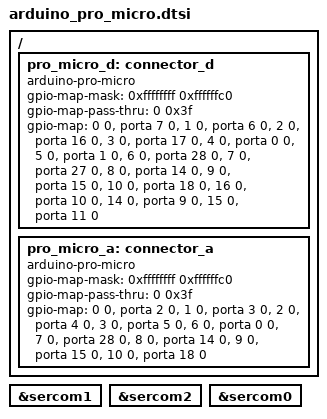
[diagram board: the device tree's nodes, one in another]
/*
 * Copyright (c) 2020 Pete Johanson
 *
 * SPDX-License-Identifier: MIT
 */

/ {
	pro_micro_d: connector_d {
		compatible = "arduino-pro-micro";
		#gpio-cells = <2>;
		gpio-map-mask = <0xffffffff 0xffffffc0>;
		gpio-map-pass-thru = <0 0x3f>;
		gpio-map
			= <0 0 &porta 7 0>		/* D0 */
			, <1 0 &porta 6 0>		/* D1 */
			, <2 0 &porta 16 0>		/* D2 */
			, <3 0 &porta 17 0>		/* D3 */
			, <4 0 &porta 0 0>		/* D4/A6 */
			, <5 0 &porta 1 0>		/* D5 */
			, <6 0 &porta 28 0>		/* D6/A7 */
			, <7 0 &porta 27 0>		/* D7 */
			, <8 0 &porta 14 0>		/* D8/A8 */
			, <9 0 &porta 15 0>		/* D9/A9 */
			, <10 0 &porta 18 0>		/* D10/A10 */
			, <16 0 &porta 10 0>	/* D16 */
			, <14 0 &porta 9 0>	/* D14 */
			, <15 0 &porta 11 0>	/* D15 */
			;
	};

	pro_micro_a: connector_a {
		compatible = "arduino-pro-micro";
		#gpio-cells = <2>;
		gpio-map-mask = <0xffffffff 0xffffffc0>;
		gpio-map-pass-thru = <0 0x3f>;
		gpio-map
			= <0 0 &porta 2 0>	/* A0 */
			, <1 0 &porta 3 0>	/* A1 */
			, <2 0 &porta 4 0>	/* A2 */
			, <3 0 &porta 5 0>	/* A3 */
			, <6 0 &porta 0 0>	/* D4/A6 */
			, <7 0 &porta 28 0>	/* D6/A7 */
			, <8 0 &porta 14 0>	/* D8/A8 */
			, <9 0 &porta 15 0>	/* D9/A9 */
			, <10 0 &porta 18 0>	/* D10/A10 */
			;
	};
};

pro_micro_i2c: &sercom1 {};
pro_micro_spi: &sercom2 {};
pro_micro_serial: &sercom0 {};
